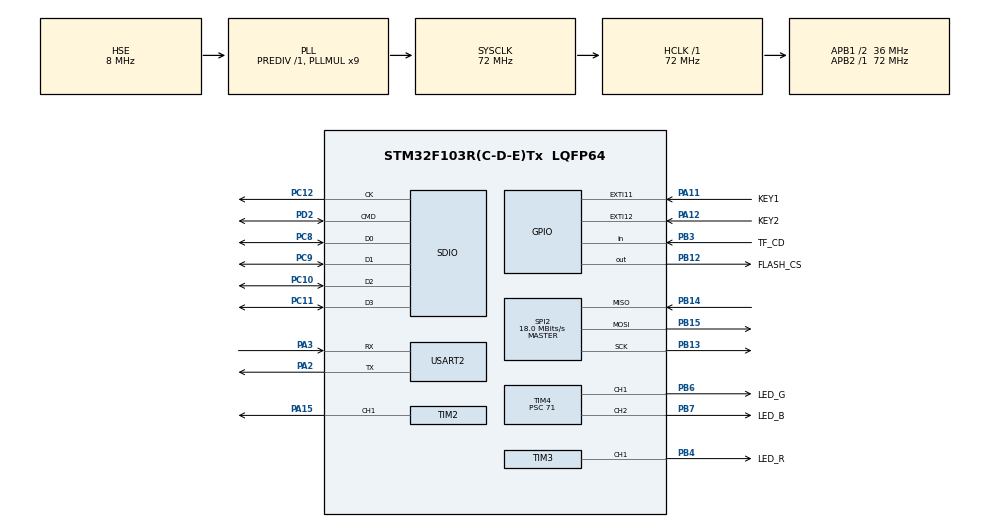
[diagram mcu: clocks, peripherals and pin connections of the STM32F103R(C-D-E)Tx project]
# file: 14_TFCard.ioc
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Mcu.Family=STM32F1
Mcu.Name=STM32F103R(C-D-E)Tx
Mcu.Package=LQFP64
NVIC.PriorityGroup=NVIC_PRIORITYGROUP_4
NVIC.USART2_IRQn=true\:0\:0\:false\:false\:true\:true\:true\:true
PA11.GPIO_Label=KEY1
PA11.GPIO_ModeDefaultEXTI=GPIO_MODE_IT_RISING_FALLING
PA11.GPIO_PuPd=GPIO_PULLUP
PA11.Signal=GPXTI11
PA12.GPIO_Label=KEY2
PA12.GPIO_ModeDefaultEXTI=GPIO_MODE_IT_RISING_FALLING
PA12.GPIO_PuPd=GPIO_PULLUP
PA12.Signal=GPXTI12
PA13.Mode=Serial_Wire
PA13.Signal=SYS_JTMS-SWDIO
PA14.Mode=Serial_Wire
PA14.Signal=SYS_JTCK-SWCLK
PA15.GPIO_Speed=GPIO_SPEED_FREQ_HIGH
PA15.Signal=S_TIM2_CH1_ETR
PA2.Mode=Asynchronous
PA2.Signal=USART2_TX
PA3.Mode=Asynchronous
PA3.Signal=USART2_RX
PB12.GPIO_Label=FLASH_CS
PB12.GPIO_PuPd=GPIO_PULLUP
PB12.GPIO_Speed=GPIO_SPEED_FREQ_HIGH
PB12.PinState=GPIO_PIN_SET
PB12.Signal=GPIO_Output
PB13.Mode=Full_Duplex_Master
PB13.Signal=SPI2_SCK
PB14.Mode=Full_Duplex_Master
PB14.Signal=SPI2_MISO
PB15.Mode=Full_Duplex_Master
PB15.Signal=SPI2_MOSI
PB3.GPIO_Label=TF_CD
PB3.GPIO_PuPd=GPIO_PULLUP
PB3.Signal=GPIO_Input
PB4.GPIO_Label=LED_R
PB4.GPIO_Speed=GPIO_SPEED_FREQ_HIGH
PB4.Signal=S_TIM3_CH1
PB6.GPIO_Label=LED_G
PB6.GPIO_Speed=GPIO_SPEED_FREQ_HIGH
PB6.Signal=S_TIM4_CH1
PB7.GPIO_Label=LED_B
PB7.GPIO_Speed=GPIO_SPEED_FREQ_HIGH
PB7.Signal=S_TIM4_CH2
PC10.Mode=SD_4_bits_Wide_bus
PC10.Signal=SDIO_D2
PC11.Mode=SD_4_bits_Wide_bus
PC11.Signal=SDIO_D3
PC12.Mode=SD_4_bits_Wide_bus
PC12.Signal=SDIO_CK
PC8.Mode=SD_4_bits_Wide_bus
PC8.Signal=SDIO_D0
PC9.Mode=SD_4_bits_Wide_bus
PC9.Signal=SDIO_D1
PD0-OSC_IN.Mode=HSE-External-Oscillator
PD0-OSC_IN.Signal=RCC_OSC_IN
PD1-OSC_OUT.Mode=HSE-External-Oscillator
PD1-OSC_OUT.Signal=RCC_OSC_OUT
PD2.Mode=SD_4_bits_Wide_bus
PD2.Signal=SDIO_CMD
ProjectManager.HeapSize=0x200
ProjectManager.StackSize=0x400
ProjectManager.TargetToolchain=MDK-ARM V5.32
RCC.AHBFreq_Value=72000000
RCC.APB1CLKDivider=RCC_HCLK_DIV2
RCC.APB1Freq_Value=36000000
RCC.APB1TimFreq_Value=72000000
RCC.APB2Freq_Value=72000000
RCC.APB2TimFreq_Value=72000000
RCC.HCLKFreq_Value=72000000
RCC.PLLMUL=RCC_PLL_MUL9
RCC.PLLSourceVirtual=RCC_PLLSOURCE_HSE
RCC.SYSCLKFreq_VALUE=72000000
RCC.SYSCLKSource=RCC_SYSCLKSOURCE_PLLCLK
RCC.USBFreq_Value=72000000
SDIO.ClockDiv=2
SH.S_TIM2_CH1_ETR.0=TIM2_CH1,PWM Generation1 CH1
SH.S_TIM3_CH1.0=TIM3_CH1,PWM Generation1 CH1
SH.S_TIM4_CH1.0=TIM4_CH1,PWM Generation1 CH1
SH.S_TIM4_CH2.0=TIM4_CH2,PWM Generation2 CH2
SPI2.CLKPhase=SPI_PHASE_2EDGE
SPI2.CLKPolarity=SPI_POLARITY_HIGH
SPI2.CalculateBaudRate=18.0 MBits/s
SPI2.Direction=SPI_DIRECTION_2LINES
SPI2.Mode=SPI_MODE_MASTER
SPI2.VirtualType=VM_MASTER
TIM1.AutoReloadPreload=TIM_AUTORELOAD_PRELOAD_ENABLE
TIM1.Period=9999
TIM1.Prescaler=71
TIM2.Channel-PWM\ Generation1\ CH1=TIM_CHANNEL_1
TIM2.OCPolarity_1=TIM_OCPOLARITY_LOW
TIM2.Period=99
TIM2.Prescaler=71
TIM3.AutoReloadPreload=TIM_AUTORELOAD_PRELOAD_ENABLE
TIM3.Channel-PWM\ Generation1\ CH1=TIM_CHANNEL_1
TIM3.OCPolarity_1=TIM_OCPOLARITY_LOW
TIM3.Period=4999
TIM3.Prescaler=71
TIM4.AutoReloadPreload=TIM_AUTORELOAD_PRELOAD_ENABLE
TIM4.Channel-PWM\ Generation1\ CH1=TIM_CHANNEL_1
TIM4.Channel-PWM\ Generation2\ CH2=TIM_CHANNEL_2
TIM4.OCPolarity_1=TIM_OCPOLARITY_LOW
TIM4.OCPolarity_2=TIM_OCPOLARITY_LOW
TIM4.Period=4999
TIM4.Prescaler=71
USART2.VirtualMode=VM_ASYNC
VP_TIM1_VS_ClockSourceINT.Mode=Internal
VP_TIM2_VS_ClockSourceINT.Mode=Internal
VP_TIM3_VS_ClockSourceINT.Mode=Internal
VP_TIM4_VS_ClockSourceINT.Mode=Internal
board=custom

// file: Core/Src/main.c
/* USER CODE BEGIN Header */
/**
 ******************************************************************************
 * @file           : main.c
 * @brief          : Main program body
 ******************************************************************************
 * @attention
 *
 * Copyright (c) 2026 STMicroelectronics.
 * All rights reserved.
 *
 * This software is licensed under terms that can be found in the LICENSE file
 * in the root directory of this software component.
 * If no LICENSE file comes with this software, it is provided AS-IS.
 *
 ******************************************************************************
 */
/* USER CODE END Header */
#include "main.h"
#include "sdio.h"
#include "spi.h"
#include "tim.h"
#include "usart.h"
#include "gpio.h"

/* USER CODE BEGIN Includes */
#include "sLog.h"
/* USER CODE END Includes */

/* USER CODE BEGIN PV */
uint8_t sucessFlag[] = "SUCESS\r\n";
HAL_SD_CardInfoTypeDef cardInfo;
/* USER CODE END PV */

void SystemClock_Config(void);

int main(void)
{

  /* MCU Configuration--------------------------------------------------------*/

  /* Reset of all peripherals, Initializes the Flash interface and the Systick. */
  HAL_Init();

  /* Configure the system clock */
  SystemClock_Config();

  /* Initialize all configured peripherals */
  MX_GPIO_Init();
  MX_TIM1_Init();
  MX_TIM3_Init();
  MX_TIM4_Init();
  MX_TIM2_Init();
  MX_USART2_UART_Init();
  MX_SPI2_Init();
  MX_SDIO_SD_Init();
  /* USER CODE BEGIN 2 */

  sLog_print("init sucess\r\n");
  HAL_SD_GetCardInfo(&hsd, &cardInfo);
  sLog_print("type: %d, version: %d, class: %d, addr: %d, blockNum: %d, blockSize: %d\r\n",
             cardInfo.CardType, cardInfo.CardVersion, cardInfo.Class, cardInfo.RelCardAdd,
             cardInfo.BlockNbr, cardInfo.BlockSize);
  sLog_print("SD card size: %.2f GB\r\n", ((float)cardInfo.BlockNbr * (float)cardInfo.BlockSize) / ((float)1000 * (float)1000 * (float)1000));
  /* USER CODE END 2 */

  /* Infinite loop */
  while (1)
  {

  }
}

void SystemClock_Config(void)
{
  RCC_OscInitTypeDef RCC_OscInitStruct = {0};
  RCC_ClkInitTypeDef RCC_ClkInitStruct = {0};

  /** Initializes the RCC Oscillators according to the specified parameters
   * in the RCC_OscInitTypeDef structure.
   */
  RCC_OscInitStruct.OscillatorType = RCC_OSCILLATORTYPE_HSE;
  RCC_OscInitStruct.HSEState = RCC_HSE_ON;
  RCC_OscInitStruct.HSEPredivValue = RCC_HSE_PREDIV_DIV1;
  RCC_OscInitStruct.HSIState = RCC_HSI_ON;
  RCC_OscInitStruct.PLL.PLLState = RCC_PLL_ON;
  RCC_OscInitStruct.PLL.PLLSource = RCC_PLLSOURCE_HSE;
  RCC_OscInitStruct.PLL.PLLMUL = RCC_PLL_MUL9;
  if (HAL_RCC_OscConfig(&RCC_OscInitStruct) != HAL_OK)
  {
    Error_Handler();
  }

  /** Initializes the CPU, AHB and APB buses clocks
   */
  RCC_ClkInitStruct.ClockType = RCC_CLOCKTYPE_HCLK | RCC_CLOCKTYPE_SYSCLK | RCC_CLOCKTYPE_PCLK1 | RCC_CLOCKTYPE_PCLK2;
  RCC_ClkInitStruct.SYSCLKSource = RCC_SYSCLKSOURCE_PLLCLK;
  RCC_ClkInitStruct.AHBCLKDivider = RCC_SYSCLK_DIV1;
  RCC_ClkInitStruct.APB1CLKDivider = RCC_HCLK_DIV2;
  RCC_ClkInitStruct.APB2CLKDivider = RCC_HCLK_DIV1;

  if (HAL_RCC_ClockConfig(&RCC_ClkInitStruct, FLASH_LATENCY_2) != HAL_OK)
  {
    Error_Handler();
  }
}

void Error_Handler(void)
{
  __disable_irq();
  while (1)
  {
  }
}
